VERSION ""

NS_ :

BS_:

BU_: UDS BRK STR ENG BMS

BO_ 1365 Fault_sts_Req: 8 Vector__XXX
 SG_ All_Fault_sts_request : 0|1@1+ (1,0) [0|0] "NA"  UDS
 SG_ All_Fault_clr_request : 8|1@1+ (1,0) [0|0] "NA"  UDS

BO_ 1364 IVS_Version_Req: 8 Vector__XXX
 SG_ SW_Version_Request : 0|1@1+ (1,0) [0|0] "NA"  UDS

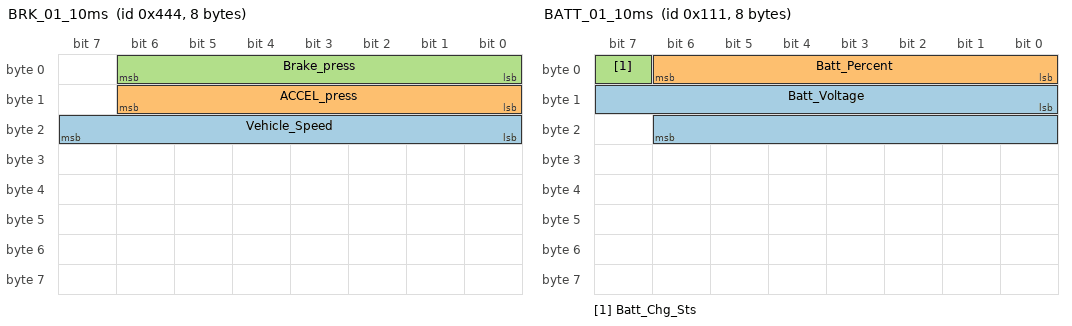
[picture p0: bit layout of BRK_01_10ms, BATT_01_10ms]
BO_ 1092 BRK_01_10ms: 8 Vector__XXX
 SG_ Vehicle_Speed : 16|8@1+ (1,0) [0|0] "km/h"  BRK
 SG_ ACCEL_press : 8|7@1+ (1,0) [0|0] "%"  BRK
 SG_ Brake_press : 0|7@1+ (1,0) [0|0] "%"  BRK

BO_ 819 STR_01_10ms: 8 Vector__XXX
 SG_ Steering_angle : 0|12@1- (1,0) [0|0] "degree"  STR

BO_ 547 ENG_02_10ms: 8 Vector__XXX
 SG_ Engine_sts : 0|2@1+ (1,0) [0|0] "NA"  ENG

BO_ 546 IGN_01_2ms: 8 Vector__XXX
 SG_ Ignition_sts : 0|1@1+ (1,0) [0|0] "NA"  ENG

BO_ 273 BATT_01_10ms: 8 Vector__XXX
 SG_ Batt_Voltage : 8|15@1+ (0.001,0) [0|0] "V"  BMS
 SG_ Batt_Percent : 0|7@1+ (1,0) [0|0] "&"  BMS
 SG_ Batt_Chg_Sts : 7|1@1+ (1,0) [0|0] "NA"  BMS

CM_ SG_ 1365 All_Fault_sts_request "모든 고장 상태 요청";
CM_ SG_ 1365 All_Fault_clr_request "모든 고장 삭제 요청";
CM_ SG_ 1364 SW_Version_Request "Software Version 정보 요청";
CM_ SG_ 1092 Vehicle_Speed "차량속도";
CM_ SG_ 1092 ACCEL_press "악셀 압력";
CM_ SG_ 1092 Brake_press "브레이크 압력";
CM_ SG_ 819 Steering_angle "핸들 각도";
CM_ SG_ 547 Engine_sts "엔진 시동 상태";
CM_ SG_ 546 Ignition_sts "엔진 시동 상태";
CM_ SG_ 273 Batt_Voltage "배터리전압값";
CM_ SG_ 273 Batt_Percent "배터리충전량";
CM_ SG_ 273 Batt_Chg_Sts "배터리충전상태";
